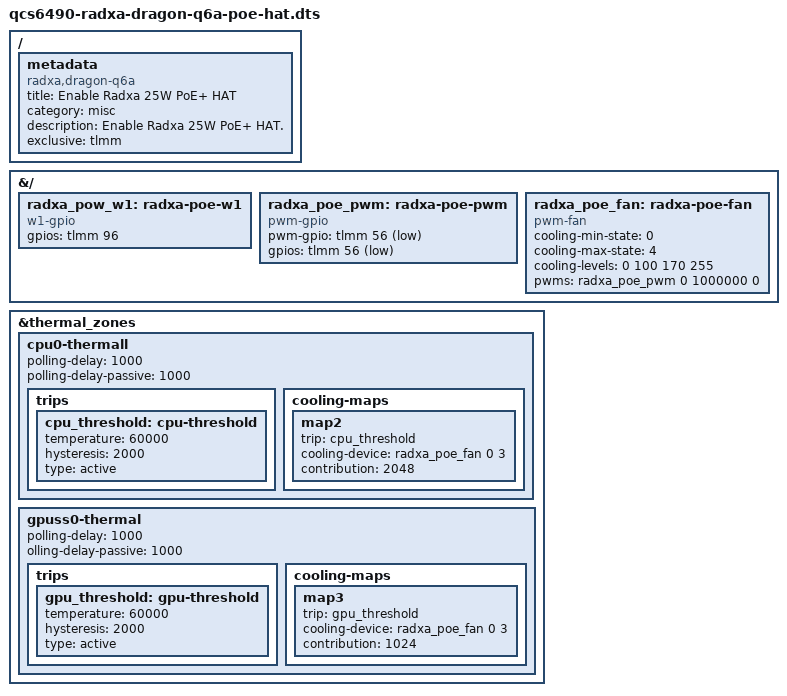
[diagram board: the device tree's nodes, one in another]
/dts-v1/;
/plugin/;

#include <dt-bindings/gpio/gpio.h>
#include <dt-bindings/pwm/pwm.h>
#include <dt-bindings/thermal/thermal.h>

/ {
	metadata {
		title = "Enable Radxa 25W PoE+ HAT";
		category = "misc";
		compatible = "radxa,dragon-q6a";
		description = "Enable Radxa 25W PoE+ HAT.";
		exclusive = "tlmm";
	};
};

&{/} {
	radxa_pow_w1: radxa-poe-w1 {
		compatible = "w1-gpio";
		gpios = <&tlmm 96 GPIO_ACTIVE_HIGH>;
		status = "okay";
	};

	radxa_poe_pwm: radxa-poe-pwm {
		compatible = "pwm-gpio";
		#pwm-cells = <3>;
		pwm-gpio = <&tlmm 56 GPIO_ACTIVE_LOW>;
		gpios = <&tlmm 56 GPIO_ACTIVE_LOW>;
	};

	radxa_poe_fan: radxa-poe-fan {
		compatible = "pwm-fan";
		#cooling-cells = <2>;
		cooling-min-state = <0>;
		cooling-max-state = <4>;
		cooling-levels = <0 100 170 255>;
		pwms = <&radxa_poe_pwm 0 1000000 0>;
	};
};

&thermal_zones {
	cpu0-thermall {
		polling-delay = <1000>;           
		polling-delay-passive = <1000>;   
		trips {
			cpu_threshold:cpu-threshold {
				temperature = <60000>;
				hysteresis = <2000>;
				type = "active";
			};
		};

		cooling-maps {
			map2 {
				trip = <&cpu_threshold>;
				cooling-device = <&radxa_poe_fan 0 3>;
				contribution = <2048>;
			};
		};
	};

	gpuss0-thermal {
		polling-delay = <1000>;           
		olling-delay-passive = <1000>;
		trips {
			gpu_threshold:gpu-threshold {
				temperature = <60000>;
				hysteresis = <2000>;
				type = "active";
			};
		};

		cooling-maps {
			map3 {
				trip = <&gpu_threshold>;
				cooling-device = <&radxa_poe_fan 0 3>;
				contribution = <1024>;
			};
		};
	};
};
